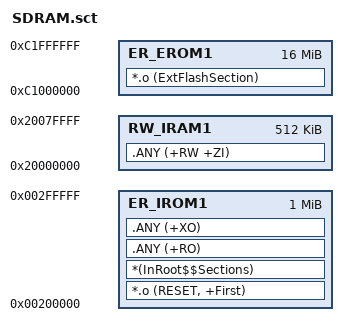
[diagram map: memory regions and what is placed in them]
; *************************************************************
; *** Scatter-Loading Description File generated by uVision ***
; *************************************************************

LR_IROM1 0x00200000 0x00100000  {    ; load region size_region
  ER_IROM1 0x00200000 0x00100000  {  ; load address = execution address
   *.o (RESET, +First)
   *(InRoot$$Sections)
   .ANY (+RO)
   .ANY (+XO)
  }
	
  RW_IRAM1 0x20000000 0x00080000  {  ; RW data
   .ANY (+RW +ZI)
  }
	
	ER_EROM1 0xC1000000 0x1000000  {  ; load address = execution address
   *.o (ExtFlashSection)
  }
}
